# HC32A4A8RITJ register map
File version: 1.0
CPU: CM4 r0p1, little endian, MPU, FPU, 4 interrupt priority bits
Registers are 32-bit, read-write, reset 0x0 unless marked. A register's access mark holds for its fields unless they carry their own. Offsets are from the block's base; [hi:lo] are bit positions; {n}, {i} and the like mark numbered series.

## CAN1 — desc CAN
Base 0x40009000
Same registers: CAN2 0x40078000
0x00 RBUF ro
0x50 TBUF
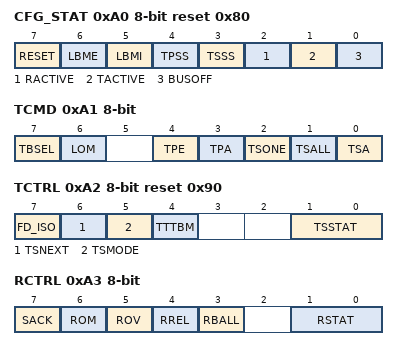
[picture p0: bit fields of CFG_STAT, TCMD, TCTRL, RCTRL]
0xA0 CFG_STAT 8-bit reset 0x80
  [7] RESET, [6] LBME, [5] LBMI, [4] TPSS, [3] TSSS, [2] RACTIVE ro, [1] TACTIVE ro, [0] BUSOFF
0xA1 TCMD 8-bit
  [7] TBSEL, [6] LOM, [4] TPE, [3] TPA, [2] TSONE, [1] TSALL, [0] TSA
0xA2 TCTRL 8-bit reset 0x90
  [7] FD_ISO, [6] TSNEXT, [5] TSMODE, [4] TTTBM, [1:0] TSSTAT ro
0xA3 RCTRL 8-bit
  [7] SACK, [6] ROM, [5] ROV ro, [4] RREL, [3] RBALL, [1:0] RSTAT ro
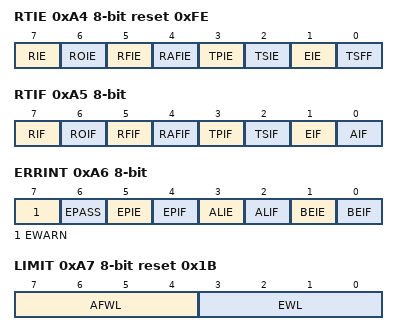
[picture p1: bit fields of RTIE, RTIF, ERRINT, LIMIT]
0xA4 RTIE 8-bit reset 0xFE
  [7] RIE, [6] ROIE, [5] RFIE, [4] RAFIE, [3] TPIE, [2] TSIE, [1] EIE, [0] TSFF ro
0xA5 RTIF 8-bit
  [7] RIF, [6] ROIF, [5] RFIF, [4] RAFIF, [3] TPIF, [2] TSIF, [1] EIF, [0] AIF
0xA6 ERRINT 8-bit
  [7] EWARN ro, [6] EPASS ro, [5] EPIE, [4] EPIF, [3] ALIE, [2] ALIF, [1] BEIE, [0] BEIF
0xA7 LIMIT 8-bit reset 0x1B
  [7:4] AFWL, [3:0] EWL
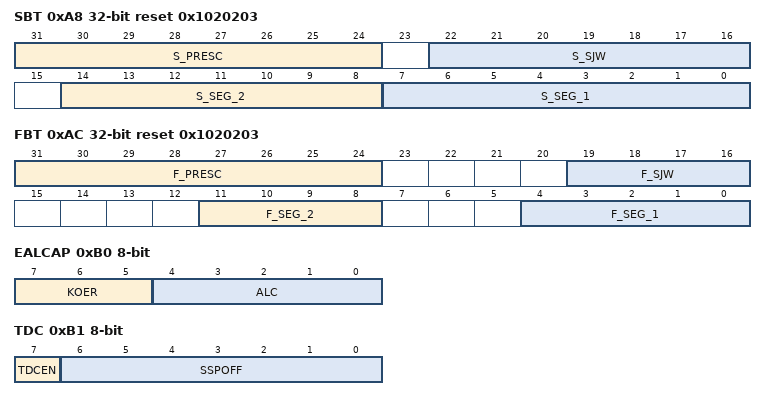
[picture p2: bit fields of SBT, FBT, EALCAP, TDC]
0xA8 SBT reset 0x1020203
  [31:24] S_PRESC, [22:16] S_SJW, [14:8] S_SEG_2, [7:0] S_SEG_1
0xAC FBT reset 0x1020203
  [31:24] F_PRESC, [19:16] F_SJW, [11:8] F_SEG_2, [4:0] F_SEG_1
0xB0 EALCAP 8-bit ro
  [7:5] KOER, [4:0] ALC
0xB1 TDC 8-bit
  [7] TDCEN, [6:0] SSPOFF
0xB2 RECNT 8-bit
0xB3 TECNT 8-bit
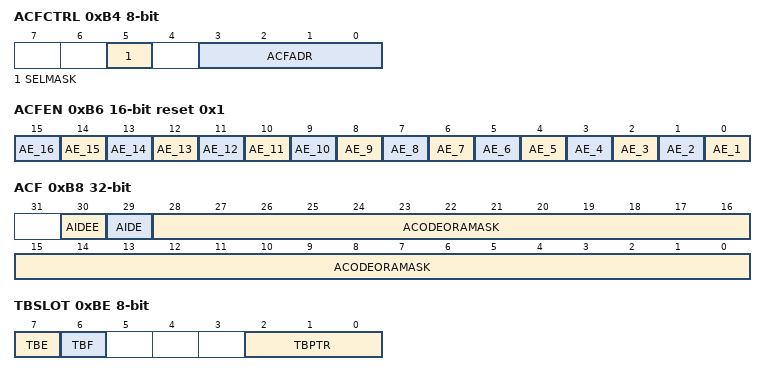
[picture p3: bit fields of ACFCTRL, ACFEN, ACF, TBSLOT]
0xB4 ACFCTRL 8-bit
  [5] SELMASK, [3:0] ACFADR
0xB6 ACFEN 16-bit reset 0x1
  [n-1] AE_{n} (n=1..16)
0xB8 ACF
  [30] AIDEE, [29] AIDE, [28:0] ACODEORAMASK
0xBE TBSLOT 8-bit
  [7] TBE, [6] TBF, [2:0] TBPTR
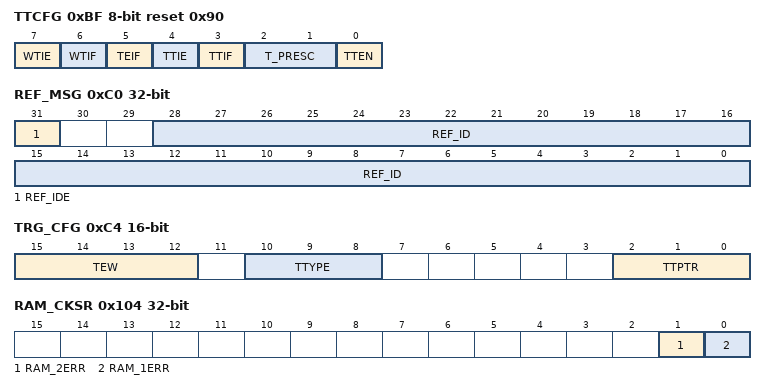
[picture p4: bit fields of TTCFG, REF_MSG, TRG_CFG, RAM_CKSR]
0xBF TTCFG 8-bit reset 0x90
  [7] WTIE, [6] WTIF, [5] TEIF, [4] TTIE, [3] TTIF, [2:1] T_PRESC, [0] TTEN
0xC0 REF_MSG
  [31] REF_IDE, [28:0] REF_ID
0xC4 TRG_CFG 16-bit
  [15:12] TEW, [10:8] TTYPE, [2:0] TTPTR
0xC6 TT_TRIG 16-bit
0xC8 TT_WTRIG 16-bit reset 0xFFFF
0x100 RAM_CKCR
  [1:0] ECCMOD
0x104 RAM_CKSR
  [1] RAM_2ERR, [0] RAM_1ERR
0x108 RAM_EIEN
  [0] EIEN
0x10C RAM_EIBIT0
0x110 RAM_EIBIT1
  [6:0] EIBIT
0x114 RAM_ECCERRADDR ro
  [10:0] ECCERRADDR

## CMP1 — desc CMP
Base 0x4004A000
Same registers: CMP3 0x4004A400
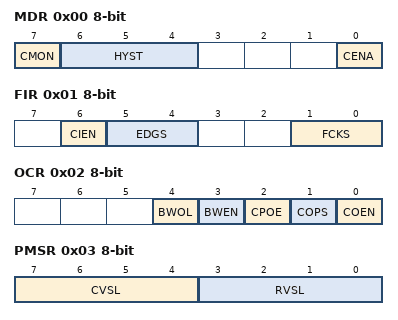
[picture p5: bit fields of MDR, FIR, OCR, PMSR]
0x00 MDR 8-bit
  [7] CMON ro, [6:4] HYST, [0] CENA
0x01 FIR 8-bit
  [6] CIEN, [5:4] EDGS, [1:0] FCKS
0x02 OCR 8-bit
  [4] BWOL, [3] BWEN, [2] CPOE, [1] COPS, [0] COEN
0x03 PMSR 8-bit
  [7:4] CVSL, [3:0] RVSL
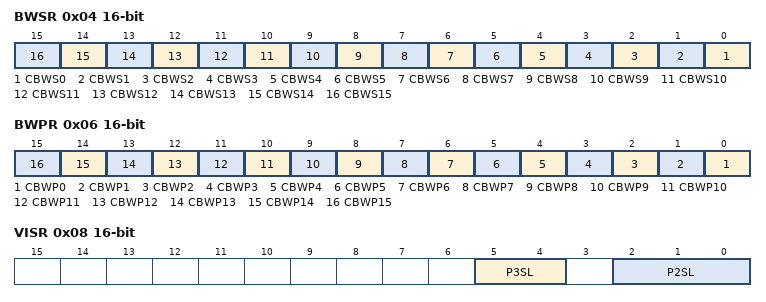
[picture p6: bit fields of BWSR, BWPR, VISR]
0x04 BWSR 16-bit
  [n] CBWS{n} (n=0..15)
0x06 BWPR 16-bit
  [n] CBWP{n} (n=0..15)
0x08 VISR 16-bit
  [5:4] P3SL, [2:0] P2SL

## CMP2 — desc CMP
Base 0x4004A010
Same registers: CMP4 0x4004A410
Registers as CMP1, without VISR; these are added or differ:
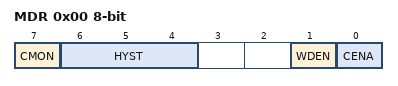
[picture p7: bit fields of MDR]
0x00 MDR 8-bit
  [7] CMON ro, [6:4] HYST, [1] WDEN, [0] CENA

## CMU
Base 0x40048000
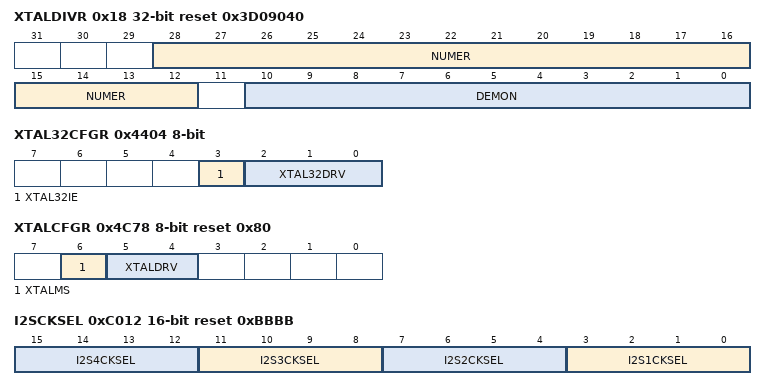
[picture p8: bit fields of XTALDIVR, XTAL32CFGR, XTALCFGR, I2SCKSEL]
0x18 XTALDIVR reset 0x3D09040
  [28:12] NUMER, [10:0] DEMON
0x1C XTALDIVCR
  [0] FRADIVEN
0x4400 XTAL32CR 8-bit
  [0] XTAL32STP
0x4404 XTAL32CFGR 8-bit
  [3] XTAL32IE, [2:0] XTAL32DRV
0x4414 XTAL32NFR 8-bit
  [1:0] XTAL32NF
0x441C LRCCR 8-bit
  [0] LRCSTP
0x4424 LRCTRM 8-bit
0x442C RTCLRCTRM 8-bit
0x4C78 XTALCFGR 8-bit reset 0x80
  [6] XTALMS, [5:4] XTALDRV
0xC010 PERICKSEL 16-bit
  [3:0] PERICKSEL
0xC012 I2SCKSEL 16-bit reset 0xBBBB
  [4n-1:4n-4] I2S{n}CKSEL (n=1..4)
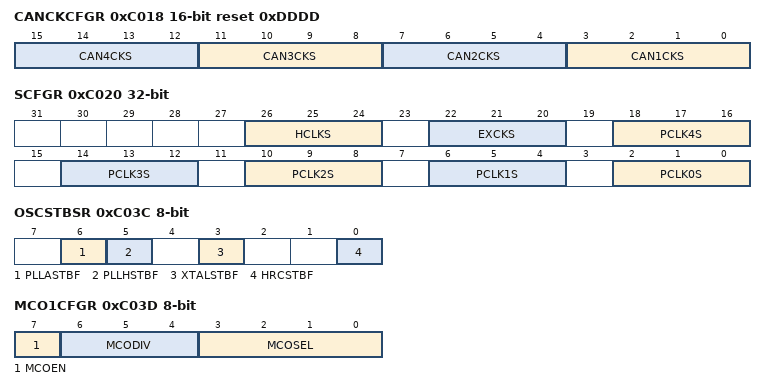
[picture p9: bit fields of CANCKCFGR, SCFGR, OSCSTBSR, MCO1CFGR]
0xC018 CANCKCFGR 16-bit reset 0xDDDD
  [4n-1:4n-4] CAN{n}CKS (n=1..4)
0xC020 SCFGR
  [26:24] HCLKS, [22:20] EXCKS, [4n+2:4n] PCLK{n}S (n=0..4)
0xC024 USBCKCFGR 8-bit reset 0x40
  [7:4] USBCKS
0xC026 CKSWR 8-bit reset 0x1
  [2:0] CKSW
0xC02A PLLHCR 8-bit reset 0x1
  [0] PLLHOFF
0xC02E PLLACR 8-bit reset 0x1
  [0] PLLAOFF
0xC032 XTALCR 8-bit reset 0x1
  [0] XTALSTP
0xC036 HRCCR 8-bit reset 0x1
  [0] HRCSTP
0xC038 MRCCR 8-bit reset 0x80
  [0] MRCSTP
0xC03C OSCSTBSR 8-bit
  [6] PLLASTBF, [5] PLLHSTBF, [3] XTALSTBF, [0] HRCSTBF
0xC03D MCO1CFGR 8-bit
  [7] MCOEN, [6:4] MCODIV, [3:0] MCOSEL
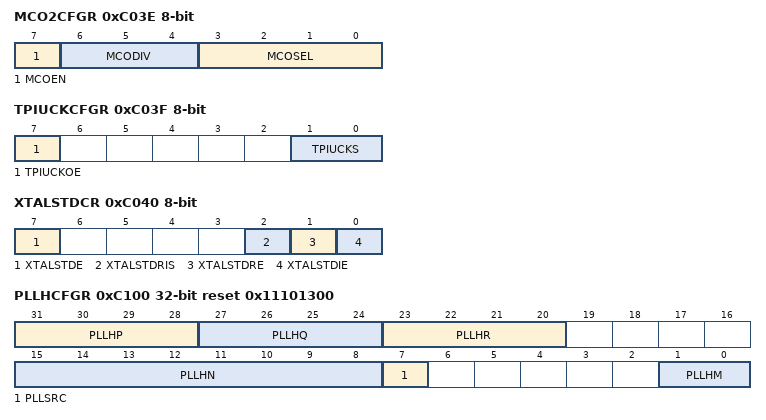
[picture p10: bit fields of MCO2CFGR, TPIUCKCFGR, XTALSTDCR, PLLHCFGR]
0xC03E MCO2CFGR 8-bit
  [7] MCOEN, [6:4] MCODIV, [3:0] MCOSEL
0xC03F TPIUCKCFGR 8-bit
  [7] TPIUCKOE, [1:0] TPIUCKS
0xC040 XTALSTDCR 8-bit
  [7] XTALSTDE, [2] XTALSTDRIS, [1] XTALSTDRE, [0] XTALSTDIE
0xC041 XTALSTDSR 8-bit
  [0] XTALSTDF
0xC061 MRCTRM 8-bit
0xC062 HRCTRM 8-bit
0xC0A2 XTALSTBCR 8-bit reset 0x5
  [3:0] XTALSTB
0xC100 PLLHCFGR reset 0x11101300
  [31:28] PLLHP, [27:24] PLLHQ, [23:20] PLLHR, [15:8] PLLHN, [7] PLLSRC, [1:0] PLLHM
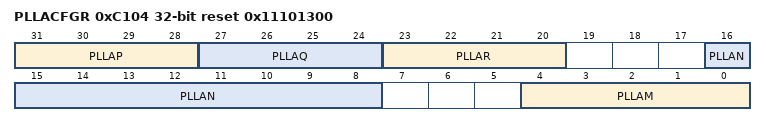
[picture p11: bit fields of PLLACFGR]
0xC104 PLLACFGR reset 0x11101300
  [31:28] PLLAP, [27:24] PLLAQ, [23:20] PLLAR, [16:8] PLLAN, [4:0] PLLAM
